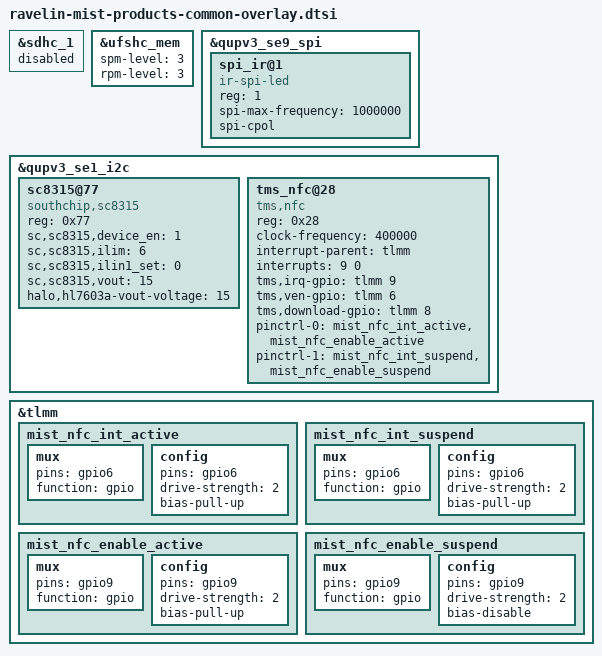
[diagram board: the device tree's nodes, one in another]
// SPDX-License-Identifier: BSD-3-Clause
/*
 * Xiaomi Mist board.
 */

#include "ravelin-xiaomi-common-overlay-base.dtsi"
#include "ravelin-xiaomi-common-overlay.dtsi"
#include "ravelin-mist-charger-overlay.dtsi"
#include "ravelin-mist-fingerprint-overlay.dtsi"

&sdhc_1 {
	status = "disabled";
};

&ufshc_mem {
	spm-level = <3>;
	rpm-level = <3>;
};

/* Stock uses Xiaomi's mispidev, LineageOS uses the lirc ir-spi driver */
&qupv3_se9_spi {
	status = "ok";

	spi_ir@1 {
		compatible = "ir-spi-led";
		reg = <1>;
		spi-max-frequency = <1000000>;
		spi-cpol;
		status = "ok";
	};
};

&qupv3_se1_i2c {
	#address-cells = <1>;
	#size-cells = <0>;
	status = "ok";

	sc8315@77 {
		compatible = "southchip,sc8315";
		reg = <0x77>;
		sc,sc8315,device_en = <1>;
		sc,sc8315,ilim = <6>;
		sc,sc8315,ilin1_set = <0>;
		sc,sc8315,vout = <15>;
		halo,hl7603a-vout-voltage = <15>;
		status = "okay";
	};

	tms_nfc@28 {
		compatible = "tms,nfc";
		reg = <0x28>;
		clock-frequency = <400000>;
		interrupt-parent = <&tlmm>;
		interrupts = <9 0>;
		interrupt-names = "nfc_irq";
		tms,irq-gpio = <&tlmm 9 0>;
		tms,ven-gpio = <&tlmm 6 0>;
		tms,download-gpio = <&tlmm 8 0>;
		pinctrl-names = "nfc_active", "nfc_suspend";
		pinctrl-0 = <&mist_nfc_int_active &mist_nfc_enable_active>;
		pinctrl-1 = <&mist_nfc_int_suspend &mist_nfc_enable_suspend>;
		status = "ok";
	};
};

/* Pin states as in stock, the labels are swapped there too */
&tlmm {
	mist_nfc_int_active: mist_nfc_int_active {
		mux {
			pins = "gpio6";
			function = "gpio";
		};

		config {
			pins = "gpio6";
			drive-strength = <2>;
			bias-pull-up;
		};
	};

	mist_nfc_int_suspend: mist_nfc_int_suspend {
		mux {
			pins = "gpio6";
			function = "gpio";
		};

		config {
			pins = "gpio6";
			drive-strength = <2>;
			bias-pull-up;
		};
	};

	mist_nfc_enable_active: mist_nfc_enable_active {
		mux {
			pins = "gpio9";
			function = "gpio";
		};

		config {
			pins = "gpio9";
			drive-strength = <2>;
			bias-pull-up;
		};
	};

	mist_nfc_enable_suspend: mist_nfc_enable_suspend {
		mux {
			pins = "gpio9";
			function = "gpio";
		};

		config {
			pins = "gpio9";
			drive-strength = <2>;
			bias-disable;
		};
	};
};
